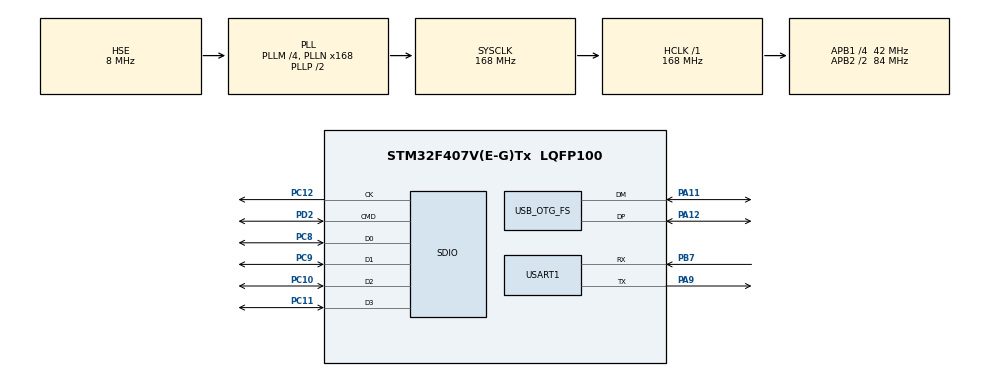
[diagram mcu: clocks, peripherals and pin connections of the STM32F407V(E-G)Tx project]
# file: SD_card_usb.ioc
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Dma.Request0=SDIO_TX
Dma.Request1=SDIO_RX
Dma.SDIO_RX.1.Direction=DMA_PERIPH_TO_MEMORY
Dma.SDIO_RX.1.FIFOMode=DMA_FIFOMODE_ENABLE
Dma.SDIO_RX.1.FIFOThreshold=DMA_FIFO_THRESHOLD_FULL
Dma.SDIO_RX.1.Instance=DMA2_Stream6
Dma.SDIO_RX.1.MemBurst=DMA_MBURST_INC4
Dma.SDIO_RX.1.MemDataAlignment=DMA_MDATAALIGN_WORD
Dma.SDIO_RX.1.MemInc=DMA_MINC_ENABLE
Dma.SDIO_RX.1.Mode=DMA_PFCTRL
Dma.SDIO_RX.1.PeriphBurst=DMA_PBURST_INC4
Dma.SDIO_RX.1.PeriphDataAlignment=DMA_PDATAALIGN_WORD
Dma.SDIO_RX.1.PeriphInc=DMA_PINC_DISABLE
Dma.SDIO_RX.1.Priority=DMA_PRIORITY_LOW
Dma.SDIO_TX.0.Direction=DMA_MEMORY_TO_PERIPH
Dma.SDIO_TX.0.FIFOMode=DMA_FIFOMODE_ENABLE
Dma.SDIO_TX.0.FIFOThreshold=DMA_FIFO_THRESHOLD_FULL
Dma.SDIO_TX.0.Instance=DMA2_Stream3
Dma.SDIO_TX.0.MemBurst=DMA_MBURST_INC4
Dma.SDIO_TX.0.MemDataAlignment=DMA_MDATAALIGN_WORD
Dma.SDIO_TX.0.MemInc=DMA_MINC_ENABLE
Dma.SDIO_TX.0.Mode=DMA_PFCTRL
Dma.SDIO_TX.0.PeriphBurst=DMA_PBURST_INC4
Dma.SDIO_TX.0.PeriphDataAlignment=DMA_PDATAALIGN_WORD
Dma.SDIO_TX.0.PeriphInc=DMA_PINC_DISABLE
Dma.SDIO_TX.0.Priority=DMA_PRIORITY_LOW
Mcu.Family=STM32F4
Mcu.Name=STM32F407V(E-G)Tx
Mcu.Package=LQFP100
NVIC.DMA2_Stream3_IRQn=true\:2\:0\:true\:false\:true\:false\:true
NVIC.DMA2_Stream6_IRQn=true\:2\:0\:true\:false\:true\:false\:true
NVIC.OTG_FS_IRQn=true\:3\:0\:true\:false\:true\:true\:true
NVIC.PriorityGroup=NVIC_PRIORITYGROUP_4
NVIC.SDIO_IRQn=true\:1\:0\:true\:false\:true\:true\:true
PA11.Mode=Device_Only
PA11.Signal=USB_OTG_FS_DM
PA12.Mode=Device_Only
PA12.Signal=USB_OTG_FS_DP
PA13.Mode=Serial_Wire
PA13.Signal=SYS_JTMS-SWDIO
PA14.Mode=Serial_Wire
PA14.Signal=SYS_JTCK-SWCLK
PA9.Mode=Asynchronous
PA9.Signal=USART1_TX
PB7.Mode=Asynchronous
PB7.Signal=USART1_RX
PC10.Mode=SD_4_bits_Wide_bus
PC10.Signal=SDIO_D2
PC11.Mode=SD_4_bits_Wide_bus
PC11.Signal=SDIO_D3
PC12.Mode=SD_4_bits_Wide_bus
PC12.Signal=SDIO_CK
PC14-OSC32_IN.Mode=LSE-External-Oscillator
PC14-OSC32_IN.Signal=RCC_OSC32_IN
PC15-OSC32_OUT.Mode=LSE-External-Oscillator
PC15-OSC32_OUT.Signal=RCC_OSC32_OUT
PC8.Mode=SD_4_bits_Wide_bus
PC8.Signal=SDIO_D0
PC9.Mode=SD_4_bits_Wide_bus
PC9.Signal=SDIO_D1
PD2.Mode=SD_4_bits_Wide_bus
PD2.Signal=SDIO_CMD
PH0-OSC_IN.Mode=HSE-External-Oscillator
PH0-OSC_IN.Signal=RCC_OSC_IN
PH1-OSC_OUT.Mode=HSE-External-Oscillator
PH1-OSC_OUT.Signal=RCC_OSC_OUT
ProjectManager.HeapSize=0x1000
ProjectManager.StackSize=0x400
ProjectManager.TargetToolchain=MDK-ARM V5.27
RCC.48MHZClocksFreq_Value=48000000
RCC.AHBFreq_Value=168000000
RCC.APB1CLKDivider=RCC_HCLK_DIV4
RCC.APB1Freq_Value=42000000
RCC.APB1TimFreq_Value=84000000
RCC.APB2CLKDivider=RCC_HCLK_DIV2
RCC.APB2Freq_Value=84000000
RCC.APB2TimFreq_Value=168000000
RCC.CortexFreq_Value=168000000
RCC.HCLKFreq_Value=168000000
RCC.HSE_VALUE=8000000
RCC.HSI_VALUE=16000000
RCC.PLLM=4
RCC.PLLN=168
RCC.PLLQ=7
RCC.PLLSourceVirtual=RCC_PLLSOURCE_HSE
RCC.SYSCLKFreq_VALUE=168000000
RCC.SYSCLKSource=RCC_SYSCLKSOURCE_PLLCLK
RCC.VCOOutputFreq_Value=336000000
SDIO.ClockDiv=2
USART1.VirtualMode=VM_ASYNC
USB_DEVICE.CLASS_NAME_FS=MSC
USB_DEVICE.VirtualMode-MSC_FS=Msc
USB_DEVICE.VirtualModeFS=Msc_FS
USB_OTG_FS.VirtualMode=Device_Only
VP_FATFS_VS_SDIO.Mode=SDIO
VP_USB_DEVICE_VS_USB_DEVICE_MSC_FS.Mode=MSC_FS
board=custom

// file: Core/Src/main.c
/* USER CODE BEGIN Header */
/**
  ******************************************************************************
  * @file           : main.c
  * @brief          : Main program body
  ******************************************************************************
  * @attention
  *
  * <h2><center>&copy; Copyright (c) 2021 STMicroelectronics.
  * All rights reserved.</center></h2>
  *
  * This software component is licensed by ST under BSD 3-Clause license,
  * the "License"; You may not use this file except in compliance with the
  * License. You may obtain a copy of the License at:
  *                        opensource.org/licenses/BSD-3-Clause
  *
  ******************************************************************************
  */
/* USER CODE END Header */
#include "main.h"
#include "dma.h"
#include "fatfs.h"
#include "sdio.h"
#include "usart.h"
#include "usb_device.h"
#include "gpio.h"

/* USER CODE BEGIN Includes */
#include <stdio.h>
#include "stm32f4xx_hal.h"
/* USER CODE END Includes */

void SystemClock_Config(void);

/* USER CODE BEGIN 0 */
/* USER CODE BEGIN 2 */

/* USER CODE END 2 */
/* USER CODE END 0 */

int main(void)
{
  /* USER CODE BEGIN 1 */
//int sdcard_status = 0;
//HAL_SD_CardCIDTypeDef sdcard_cid;

  /* USER CODE END 1 */

  /* MCU Configuration--------------------------------------------------------*/

  /* Reset of all peripherals, Initializes the Flash interface and the Systick. */
  HAL_Init();

  /* Configure the system clock */
  SystemClock_Config();

  /* Initialize all configured peripherals */
  MX_GPIO_Init();
  MX_DMA_Init();
  MX_SDIO_SD_Init();
  MX_USART1_UART_Init();
  MX_FATFS_Init();
  MX_USB_DEVICE_Init();

  /* Infinite loop */
  /* USER CODE BEGIN WHILE */
	/* USER CODE BEGIN 2 */
//printf("Micro SD Card Test...\r\n");

///* 检测SD卡是否正常（处于数据传输模式的传输状态） */
//sdcard_status = HAL_SD_GetCardState(&hsd);
//if(sdcard_status == HAL_SD_CARD_TRANSFER)
//{
//    printf("SD card init ok!\r\n\r\n");

//    //打印SD卡基本信息
//    printf("SD card information!\r\n");
//    printf("CardCapacity: %llu\r\n",((unsigned long long)hsd.SdCard.BlockSize*hsd.SdCard.BlockNbr));
//    printf("CardBlockSize: %d \r\n",hsd.SdCard.BlockSize);
//    printf("RCA: %d \r\n",hsd.SdCard.RelCardAdd);
//    printf("CardType: %d \r\n",hsd.SdCard.CardType);

//    //读取并打印SD卡的CID信息
//    HAL_SD_GetCardCID(&hsd,&sdcard_cid);
//    printf("ManufacturerID: %d \r\n",sdcard_cid.ManufacturerID);
//}
//else
//{
//    printf("SD card init fail!\r\n" );
//	  printf("code:%d",sdcard_status);
//    return 0;
//}
/* USER CODE END 2 */
  while (1)
  {
    /* USER CODE END WHILE */

  }
}

void SystemClock_Config(void)
{
  RCC_OscInitTypeDef RCC_OscInitStruct = {0};
  RCC_ClkInitTypeDef RCC_ClkInitStruct = {0};

  /** Configure the main internal regulator output voltage
  */
  __HAL_RCC_PWR_CLK_ENABLE();
  __HAL_PWR_VOLTAGESCALING_CONFIG(PWR_REGULATOR_VOLTAGE_SCALE1);
  /** Initializes the RCC Oscillators according to the specified parameters
  * in the RCC_OscInitTypeDef structure.
  */
  RCC_OscInitStruct.OscillatorType = RCC_OSCILLATORTYPE_HSE;
  RCC_OscInitStruct.HSEState = RCC_HSE_ON;
  RCC_OscInitStruct.PLL.PLLState = RCC_PLL_ON;
  RCC_OscInitStruct.PLL.PLLSource = RCC_PLLSOURCE_HSE;
  RCC_OscInitStruct.PLL.PLLM = 4;
  RCC_OscInitStruct.PLL.PLLN = 168;
  RCC_OscInitStruct.PLL.PLLP = RCC_PLLP_DIV2;
  RCC_OscInitStruct.PLL.PLLQ = 7;
  if (HAL_RCC_OscConfig(&RCC_OscInitStruct) != HAL_OK)
  {
    Error_Handler();
  }
  /** Initializes the CPU, AHB and APB buses clocks
  */
  RCC_ClkInitStruct.ClockType = RCC_CLOCKTYPE_HCLK|RCC_CLOCKTYPE_SYSCLK
                              |RCC_CLOCKTYPE_PCLK1|RCC_CLOCKTYPE_PCLK2;
  RCC_ClkInitStruct.SYSCLKSource = RCC_SYSCLKSOURCE_PLLCLK;
  RCC_ClkInitStruct.AHBCLKDivider = RCC_SYSCLK_DIV1;
  RCC_ClkInitStruct.APB1CLKDivider = RCC_HCLK_DIV4;
  RCC_ClkInitStruct.APB2CLKDivider = RCC_HCLK_DIV2;

  if (HAL_RCC_ClockConfig(&RCC_ClkInitStruct, FLASH_LATENCY_5) != HAL_OK)
  {
    Error_Handler();
  }
}

void Error_Handler(void)
{
}

/************************ (C) COPYRIGHT STMicroelectronics *****END OF FILE****/
